# PIC32CX1025SG41100 device description
Architecture: CORTEX-M4; Family: PIC32CX; Series: PIC32CXSG41
Registers are 32-bit, read-write, reset 0x0 unless marked. A register's access mark holds for its fields unless they carry their own. Offsets are from the block's base; [hi:lo] are bit positions; {n}, {i} and the like mark numbered series; 'fields as' and 'values as' point back to an identical list; <NAME> marks a mode.

## FPU — Floating Point Unit
Instances: FPU 0xE000EF30
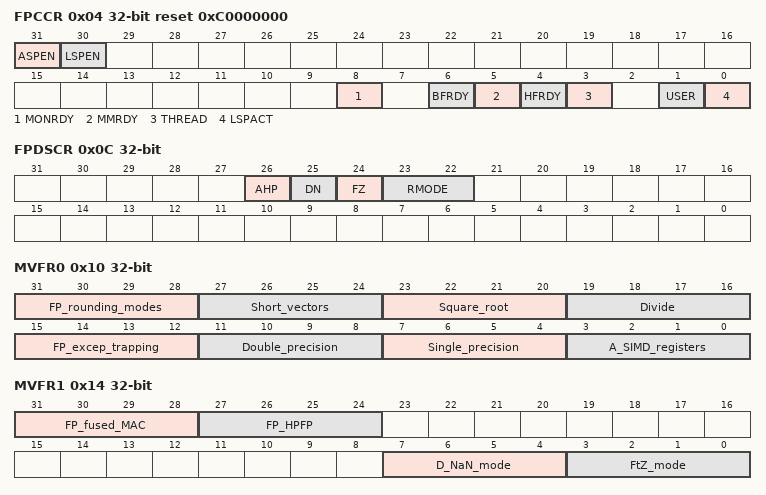
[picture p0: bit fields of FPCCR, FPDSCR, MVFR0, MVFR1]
0x04 FPCCR reset 0xC0000000 — Floating-Point Context Control Register
  [31] ASPEN, [30] LSPEN, [8] MONRDY, [6] BFRDY, [5] MMRDY, [4] HFRDY, [3] THREAD, [1] USER, [0] LSPACT
0x08 FPCAR reset not defined — Floating-Point Context Address Register
  [31:3] ADDRESS — Address for FP registers in exception stack frame
0x0C FPDSCR — Floating-Point Default Status Control Register
  [26] AHP — Default value for FPSCR.AHP
  [25] DN — Default value for FPSCR.DN
  [24] FZ — Default value for FPSCR.FZ
  [23:22] RMODE — Default value for FPSCR.RMODE
    0=RN (Round to Nearest); 1=RP (Round towards Positive Infinity); 2=RM (Round towards Negative Infinity); 3=RZ (Round towards Zero)
0x10 MVFR0 ro reset not defined — Media and FP Feature Register 0
  [31:28] FP_rounding_modes, [27:24] Short_vectors, [23:20] Square_root, [19:16] Divide, [15:12] FP_excep_trapping, [11:8] Double_precision, [7:4] Single_precision, [3:0] A_SIMD_registers
0x14 MVFR1 ro reset not defined — Media and FP Feature Register 1
  [31:28] FP_fused_MAC, [27:24] FP_HPFP, [7:4] D_NaN_mode, [3:0] FtZ_mode

## ITM — Instrumentation Trace Macrocell
Instances: ITM 0xE0000000
{0x0+4i} PORT[{i}] (i=0..31) wo reset not defined — ITM Stimulus Port Registers
  [7:0] PORT <BYTE>, [15:0] PORT <HWORD>, [31:0] PORT <WORD>
0xE00 TER reset not defined — ITM Trace Enable Register
0xE40 TPR reset not defined — ITM Trace Privilege Register
  [3:0] PRIVMASK
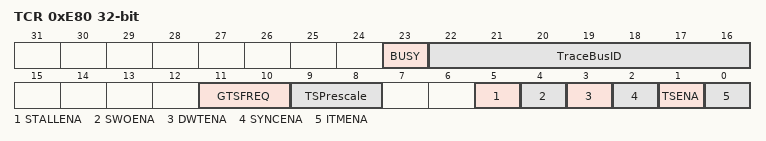
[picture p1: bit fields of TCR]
0xE80 TCR reset not defined — ITM Trace Control Register
  [23] BUSY, [22:16] TraceBusID, [11:10] GTSFREQ, [9:8] TSPrescale, [5] STALLENA, [4] SWOENA, [3] DWTENA, [2] SYNCENA, [1] TSENA, [0] ITMENA
0xEF8 IWR wo reset not defined — ITM Integration Write Register
  [0] ATVALIDM
0xEFC IRR ro reset not defined — ITM Integration Read Register
  [0] ATREADYM
0xFD0 PID4 ro reset 0x4 — ITM Peripheral Identification Register #4
{0xFC0+4i} PID{i} ro (i=5..7) — ITM Peripheral Identification Register #{i}
0xFE0 PID0 ro reset 0x1 — ITM Peripheral Identification Register #0
0xFE4 PID1 ro reset 0xB0 — ITM Peripheral Identification Register #1
0xFE8 PID2 ro reset 0x3B — ITM Peripheral Identification Register #2
0xFEC PID3 ro — ITM Peripheral Identification Register #3
0xFF0 CID0 ro reset 0xD — ITM Component Identification Register #0
0xFF4 CID1 ro reset 0xE0 — ITM Component Identification Register #1
0xFF8 CID2 ro reset 0x5 — ITM Component Identification Register #2
0xFFC CID3 ro reset 0xB1 — ITM Component Identification Register #3

## MPU — Memory Protection Unit
Instances: MPU 0xE000ED90
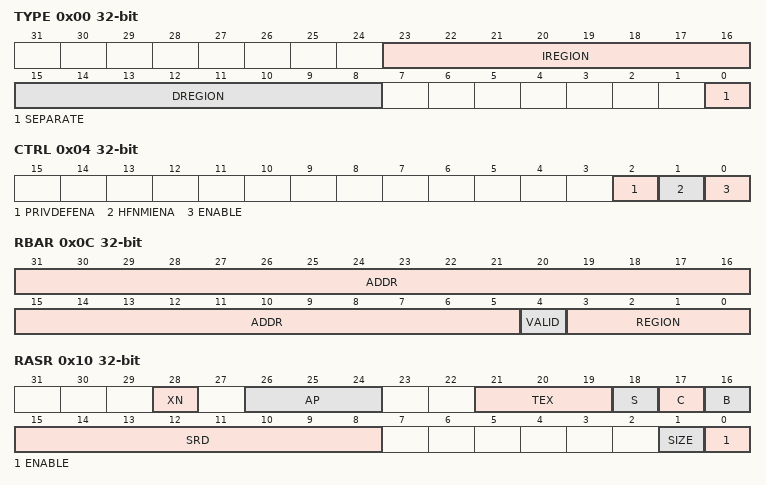
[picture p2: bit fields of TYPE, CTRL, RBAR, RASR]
0x00 TYPE ro reset not defined — MPU Type Register
  [23:16] IREGION — Number of Instruction Regions
  [15:8] DREGION — Number of Data Regions
  [0] SEPARATE — Separate instruction and Data Memory MapsRegions
0x04 CTRL reset not defined — MPU Control Register
  [2] PRIVDEFENA — Enables privileged software access to default memory map
  [1] HFNMIENA — Enable Hard Fault and NMI handlers
  [0] ENABLE — MPU Enable
0x08 RNR reset not defined — MPU Region Number Register
  [7:0] REGION — Region referenced by RBAR and RASR
0x0C RBAR reset not defined — MPU Region Base Address Register
  [31:5] ADDR — Region base address
  [4] VALID — Region number valid
  [3:0] REGION — Region number
0x10 RASR reset not defined — MPU Region Attribute and Size Register
  [28] XN — Execute Never Attribute
  [26:24] AP — Access Permission
  [21:19] TEX — TEX bit
  [18] S — Shareable bit
  [17] C — Cacheable bit
  [16] B — Bufferable bit
  [15:8] SRD — Sub-region disable
  [1] SIZE — Region Size
  [0] ENABLE — Region Enable
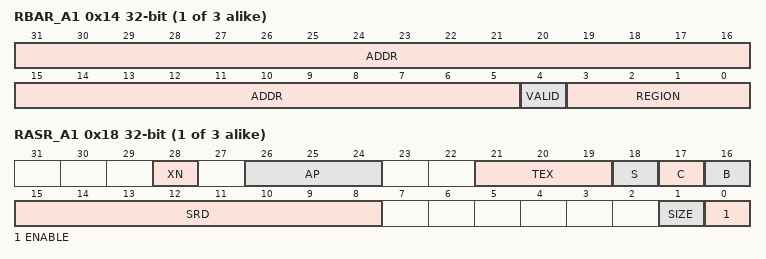
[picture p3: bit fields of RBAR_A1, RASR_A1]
{0xC+8i} RBAR_A{i} reset not defined (i=1..3) — MPU Alias {i} Region Base Address Register
  fields as RBAR
{0x10+8i} RASR_A{i} reset not defined (i=1..3) — MPU Alias {i} Region Attribute and Size Register
  fields as RASR
